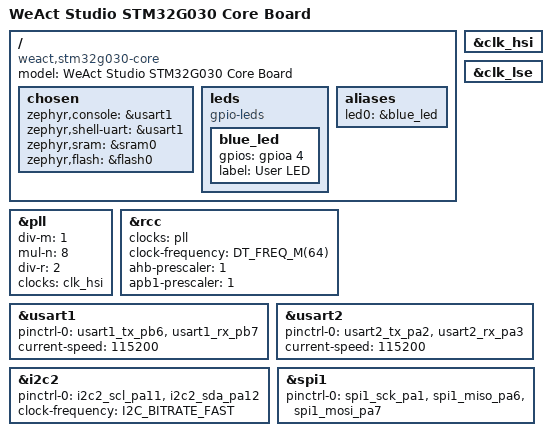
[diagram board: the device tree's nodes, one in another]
/*
 * Copyright (c) 2025 Siratul Islam
 *
 * SPDX-License-Identifier: Apache-2.0
 */

/dts-v1/;
#include <st/g0/stm32g030X6.dtsi>
#include <st/g0/stm32g030f6px-pinctrl.dtsi>
#include <zephyr/dt-bindings/input/input-event-codes.h>

/ {
	model = "WeAct Studio STM32G030 Core Board";
	compatible = "weact,stm32g030-core";

	chosen {
		zephyr,console = &usart1;
		zephyr,shell-uart = &usart1;
		zephyr,sram = &sram0;
		zephyr,flash = &flash0;
	};

	leds: leds {
		compatible = "gpio-leds";

		blue_led: blue_led {
			gpios = <&gpioa 4 GPIO_ACTIVE_HIGH>;
			label = "User LED";
		};
	};

	aliases {
		led0 = &blue_led;
	};
};

&clk_hsi {
	status = "okay";
};

&clk_lse {
	status = "okay";
};

&pll {
	div-m = <1>;
	mul-n = <8>;
	div-r = <2>;
	clocks = <&clk_hsi>;
	status = "okay";
};

&rcc {
	clocks = <&pll>;
	clock-frequency = <DT_FREQ_M(64)>;
	ahb-prescaler = <1>;
	apb1-prescaler = <1>;
};

&usart1 {
	pinctrl-0 = <&usart1_tx_pb6 &usart1_rx_pb7>;
	pinctrl-names = "default";
	current-speed = <115200>;
	status = "okay";
};

&usart2 {
	pinctrl-0 = <&usart2_tx_pa2 &usart2_rx_pa3>;
	pinctrl-names = "default";
	current-speed = <115200>;
	status = "okay";
};

&i2c2 {
	pinctrl-0 = <&i2c2_scl_pa11 &i2c2_sda_pa12>;
	pinctrl-names = "default";
	clock-frequency = <I2C_BITRATE_FAST>;
	status = "okay";
};

&spi1 {
	pinctrl-0 = <&spi1_sck_pa1 &spi1_miso_pa6 &spi1_mosi_pa7>;
	pinctrl-names = "default";
	status = "okay";
};
